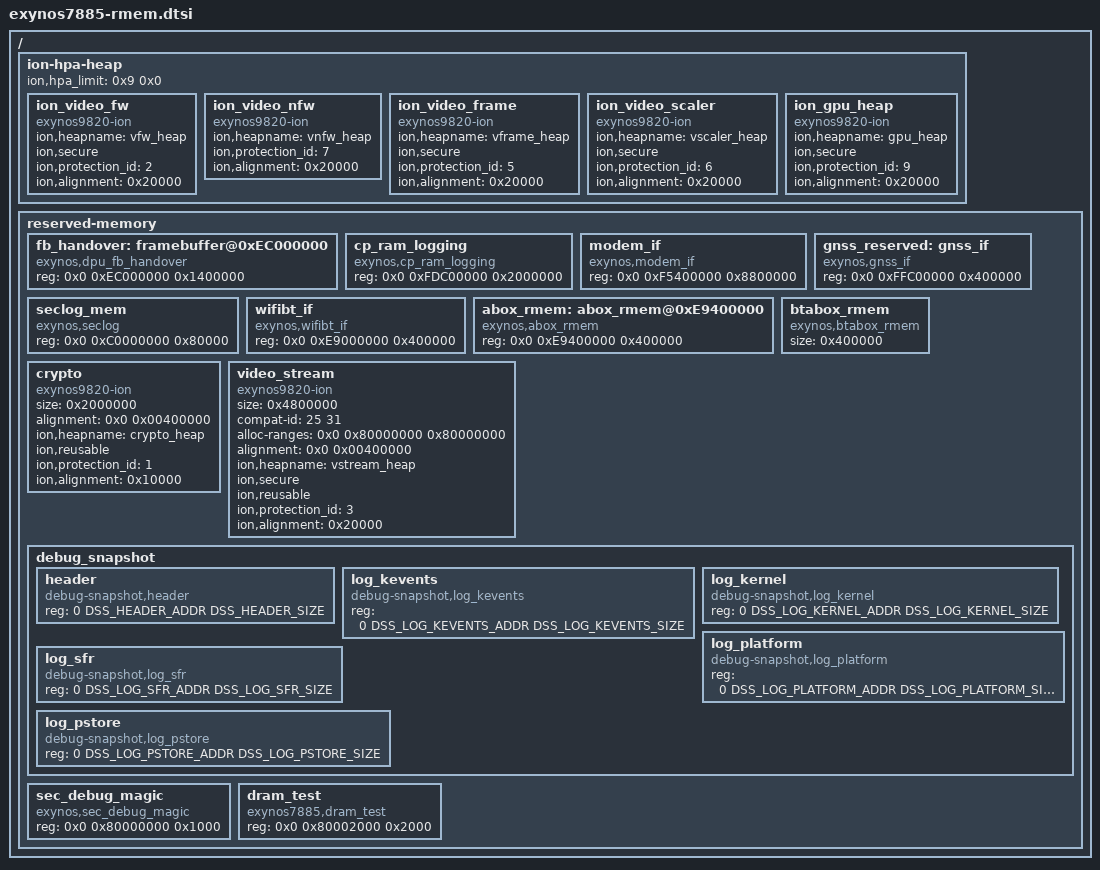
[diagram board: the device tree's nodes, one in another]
/*
 * SAMSUNG EXYNOS device tree source for reserved-memory
 *
 * Copyright (c) 2015 Samsung Electronics Co., Ltd.
 *		http://www.samsung.com
 *
 * This program is free software; you can redistribute it and/or modify
 * it under the terms of the GNU General Public License version 2 as
 * published by the Free Software Foundation.
*/

#include <dt-bindings/soc/samsung/debug-snapshot-table.h>

/memreserve/ 0xE0000000 0xD00000;

/ {
	ion-hpa-heap {
		#address-cells = <0x2>;
		#size-cells = <0x1>;
		ranges;
		ion,hpa_limit = <0x9 0x0>;

		ion_video_fw {
			compatible = "exynos9820-ion";
			ion,heapname = "vfw_heap";
			ion,secure;
			ion,protection_id = <2>;
			ion,alignment = <0x20000>;
		};

		ion_video_nfw {
			compatible = "exynos9820-ion";
			ion,heapname = "vnfw_heap";
			ion,protection_id = <7>;
			ion,alignment = <0x20000>;
		};

		ion_video_frame {
			compatible = "exynos9820-ion";
			ion,heapname = "vframe_heap";
			ion,secure;
			ion,protection_id = <5>;
			ion,alignment = <0x20000>;
		};

		ion_video_scaler {
			compatible = "exynos9820-ion";
			ion,heapname = "vscaler_heap";
			ion,secure;
			ion,protection_id = <6>;
			ion,alignment = <0x20000>;
		};

		ion_gpu_heap {
			compatible = "exynos9820-ion";
			ion,heapname = "gpu_heap";
			ion,secure;
			ion,protection_id = <9>;
			ion,alignment = <0x20000>;
		};
	};

	reserved-memory {
		#address-cells = <2>;
		#size-cells = <1>;
		ranges;

		fb_handover: framebuffer@0xEC000000 {
			compatible = "exynos,dpu_fb_handover";
			/* 1 full screen size = lcd_width * lcd_height * 4 */
			reg = <0x0 0xEC000000 0x1400000>;
		};

		cp_ram_logging {
			compatible = "exynos,cp_ram_logging";
			reg = <0x0 0xFDC00000 0x2000000>;
		};

		modem_if {
			compatible = "exynos,modem_if";
			reg = <0x0 0xF5400000 0x8800000>;
		};

		gnss_reserved: gnss_if {
			compatible = "exynos,gnss_if";
			reg = <0x0 0xFFC00000 0x400000>;
		};

		seclog_mem {
			compatible = "exynos,seclog";
			reg = <0x0 0xC0000000 0x80000>;
		};

		wifibt_if {
			compatible = "exynos,wifibt_if";
			reg = <0x0 0xE9000000 0x400000>;
		};

		abox_rmem: abox_rmem@0xE9400000 {
			compatible = "exynos,abox_rmem";
			reg = <0x0 0xE9400000 0x400000>;
		};


		btabox_rmem {
			compatible = "exynos,btabox_rmem";
			size = <0x400000>;
		};

		crypto {
			compatible = "exynos9820-ion";
			size = <0x2000000>;
			alignment = <0x0 0x00400000>;
			ion,heapname = "crypto_heap";
			ion,reusable;
			ion,protection_id = <1>;
			ion,alignment = <0x10000>;
		};

		video_stream {
			compatible = "exynos9820-ion";
			/* TUI : 1080x2220 32bpp 3frames < 28MiB*/
			/* DRM : 72 MiB */
			size = <0x4800000>;
			compat-id = <25 31>;
			alloc-ranges = <0x0 0x80000000 0x80000000>;
			alignment = <0x0 0x00400000>;
			ion,heapname = "vstream_heap";
			ion,secure;
			ion,reusable;
			ion,protection_id = <3>;
			ion,alignment = <0x20000>;
		};

		debug_snapshot {
			#address-cells = <2>;
			#size-cells = <1>;

			header {
				compatible = "debug-snapshot,header";
				reg = <0 DSS_HEADER_ADDR DSS_HEADER_SIZE>;
			};

			log_kevents {
				compatible = "debug-snapshot,log_kevents";
				reg = <0 DSS_LOG_KEVENTS_ADDR DSS_LOG_KEVENTS_SIZE>;
			};

			log_kernel {
				compatible = "debug-snapshot,log_kernel";
				reg = <0 DSS_LOG_KERNEL_ADDR DSS_LOG_KERNEL_SIZE>;
			};

			log_platform {
				compatible = "debug-snapshot,log_platform";
				reg = <0 DSS_LOG_PLATFORM_ADDR DSS_LOG_PLATFORM_SIZE>;
			};

			log_sfr {
				compatible = "debug-snapshot,log_sfr";
				reg = <0 DSS_LOG_SFR_ADDR DSS_LOG_SFR_SIZE>;
			};

			log_pstore {
				compatible = "debug-snapshot,log_pstore";
				reg = <0 DSS_LOG_PSTORE_ADDR DSS_LOG_PSTORE_SIZE>;
			};
		};

		sec_debug_magic {
			compatible = "exynos,sec_debug_magic";
			reg = <0x0 0x80000000 0x1000>;
		};

		dram_test {
			compatible = "exynos7885,dram_test";
			reg = <0x0 0x80002000 0x2000>;
		};
	};
};
